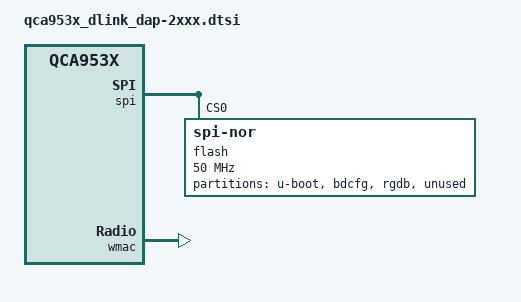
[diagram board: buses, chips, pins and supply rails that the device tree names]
// SPDX-License-Identifier: GPL-2.0-or-later OR MIT

#include "qca953x.dtsi"

#include <dt-bindings/gpio/gpio.h>
#include <dt-bindings/input/input.h>

&spi {
	status = "okay";

	flash@0 {
		compatible = "jedec,spi-nor";
		reg = <0>;
		spi-max-frequency = <50000000>;

		partitions: partitions {
			compatible = "fixed-partitions";
			#address-cells = <1>;
			#size-cells = <1>;

			partition@0 {
				label = "u-boot";
				reg = <0x0 0x40000>;
				read-only;
			};

			partition@40000 {
				label = "bdcfg";
				reg = <0x40000 0x10000>;
				read-only;
			};

			partition@50000 {
				label = "rgdb";
				reg = <0x50000 0x10000>;
				read-only;
			};

			partition@60000 {
				label = "unused";
				reg = <0x60000 0x10000>;
				read-only;
			};
		};
	};
};

&wmac {
	status = "okay";

	mtd-cal-data = <&art 0x1000>;
};
